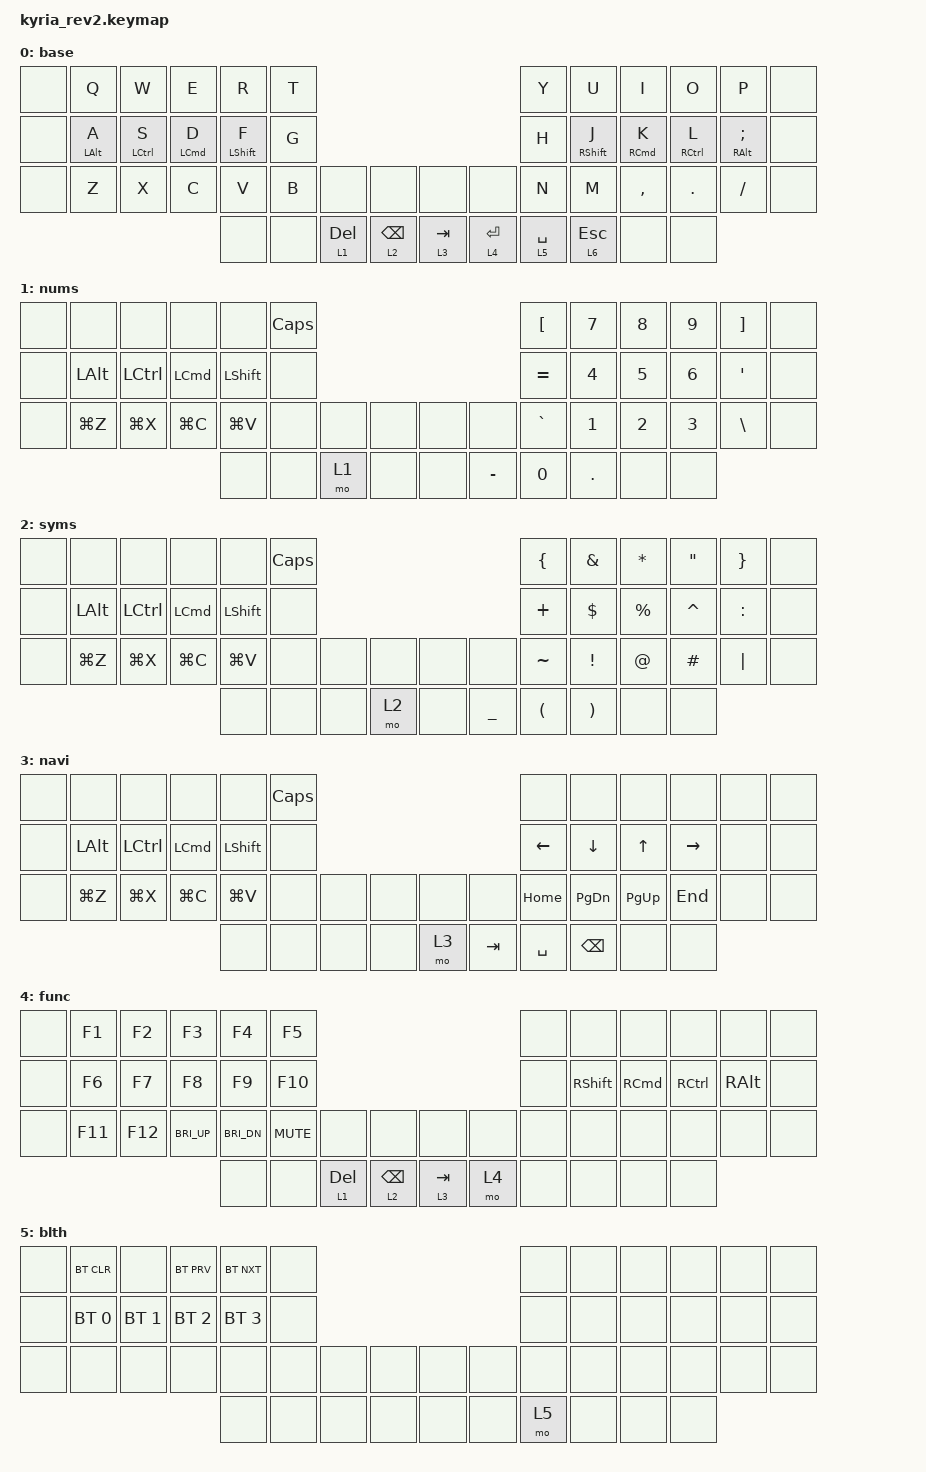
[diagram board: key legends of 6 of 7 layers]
/*
 * Copyright (c) 2020 The ZMK Contributors
 *
 * SPDX-License-Identifier: MIT
 */

#include <behaviors.dtsi>
#include <dt-bindings/zmk/bt.h>
#include <dt-bindings/zmk/keys.h>

/ {
    keymap {
        compatible = "zmk,keymap";

        default_layer { // Layer 0
            display-name = "base";
            bindings = <
               &none &kp Q      &kp W       &kp E      &kp R       &kp T                                                   &kp Y &kp U       &kp I      &kp O       &kp P         &none
               &none &mt LALT A &mt LCTRL S &mt LCMD D &mt LSHFT F &kp G                                                   &kp H &mt RSHFT J &mt RCMD K &mt RCTRL L &mt RALT SEMI &none
               &none &kp Z      &kp X       &kp C      &kp V       &kp B     &none      &none        &none     &none       &kp N &kp M       &kp COMMA  &kp DOT     &kp FSLH      &none
                                                       &none &none &lt 1 DEL &lt 2 BSPC &lt 3 TAB    &lt 4 RET &lt 5 SPACE &lt 6 ESC &none &none
            >;

            sensor-bindings = <&inc_dec_kp C_VOL_UP C_VOL_DN &inc_dec_kp PG_UP PG_DN>;
        };

        number_layer { // Layer 1
            display-name = "nums";
            bindings = <
               &none &none     &none     &none     &none     &kp CAPS                              &kp LBKT  &kp N7 &kp N8 &kp N9 &kp RBKT &none
               &none &kp LALT  &kp LCTRL &kp LCMD  &kp LSHFT &none                                 &kp EQUAL &kp N4 &kp N5 &kp N6 &kp SQT  &none
               &none &kp LG(Z) &kp LG(X) &kp LG(C) &kp LG(V) &none &none &none    &none     &none  &kp GRAVE &kp N1 &kp N2 &kp N3 &kp BSLH &none
                                                 &none &none &mo 1 &none &none    &kp MINUS &kp N0 &kp DOT &none &none
            >;
        };

        symbol_layer { // Layer 2
            display-name = "syms";
            bindings = <
               &none &none     &none     &none     &none     &kp CAPS                                &kp LBRC  &kp AMPS &kp STAR  &kp DQT   &kp RBRC  &none
               &none &kp LALT  &kp LCTRL &kp LCMD  &kp LSHFT &none                                   &kp PLUS  &kp DLLR &kp PRCNT &kp CARET &kp COLON &none
               &none &kp LG(Z) &kp LG(X) &kp LG(C) &kp LG(V) &none &none &none    &none     &none    &kp TILDE &kp EXCL &kp AT    &kp HASH  &kp PIPE  &none
                                                 &none &none &none &mo 2 &none    &kp UNDER &kp LPAR &kp RPAR &none &none
            >;
        };

        navigation_layer { // Layer 3
            display-name = "navi";
            bindings = <
               &none &none     &none     &none     &none     &kp CAPS                               &none    &none     &none     &none     &none &none
               &none &kp LALT  &kp LCTRL &kp LCMD  &kp LSHFT &none                                  &kp LEFT &kp DOWN  &kp UP    &kp RIGHT &none &none
               &none &kp LG(Z) &kp LG(X) &kp LG(C) &kp LG(V) &none &none &none    &none   &none     &kp HOME &kp PG_DN &kp PG_UP &kp END   &none &none
                                                 &none &none &none &none &mo 3    &kp TAB &kp SPACE &kp BSPC &none &none
            >;
        };

        fkeys_layer { // Layer 4
            display-name = "func";
            bindings = <
               &none &kp F1  &kp F2  &kp F3       &kp F4       &kp F5                                         &none &none     &none    &none     &none    &none
               &none &kp F6  &kp F7  &kp F8       &kp F9       &kp F10                                        &none &kp RSHFT &kp RCMD &kp RCTRL &kp RALT &none
               &none &kp F11 &kp F12 &kp C_BRI_UP &kp C_BRI_DN &kp C_MUTE &none      &none        &none &none &none &none     &none    &none     &none    &none
                                                   &none &none &lt 1 DEL  &lt 2 BSPC &lt 3 TAB    &mo 4 &none &none &none &none
            >;
        };

        bluetooth_layer { // Layer 5
            display-name = "blth";
            bindings = <
               &none &bt BT_CLR &none          &bt BT_PRV   &bt BT_NXT   &none                            &none &none &none &none &none &none
               &none &bt BT_SEL 0 &bt BT_SEL 1 &bt BT_SEL 2 &bt BT_SEL 3 &none                            &none &none &none &none &none &none
               &none &none      &none          &none        &none        &none &none &none    &none &none &none &none &none &none &none &none
                                                             &none &none &none &none &none    &none &mo 5 &none &none &none
            >;
        };

        config_layer { // Layer 6
            display-name = "conf";
            bindings = <
               &none &soft_off &none &none &none &studio_unlock                   &none &none &none &none &none &none
               &none &none     &none &none &none &none                            &none &none &none &none &none &none
               &none &none     &none &none &none &none                            &none &none &none &none &none &none
                                          &none &none &none &none &none    &none &none &mo 6 &none &none
            >;
        };
    };
};
